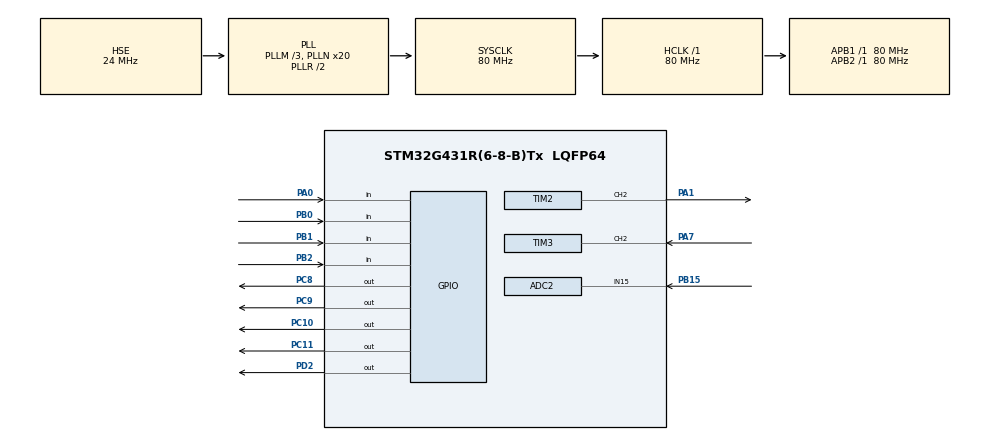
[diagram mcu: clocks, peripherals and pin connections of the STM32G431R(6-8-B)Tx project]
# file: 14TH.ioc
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ADC2.Channel-0\#ChannelRegularConversion=ADC_CHANNEL_15
ADC2.NbrOfConversionFlag=1
ADC2.OffsetNumber-0\#ChannelRegularConversion=ADC_OFFSET_NONE
ADC2.Rank-0\#ChannelRegularConversion=1
ADC2.SamplingTime-0\#ChannelRegularConversion=ADC_SAMPLETIME_2CYCLES_5
Mcu.Family=STM32G4
Mcu.Name=STM32G431R(6-8-B)Tx
Mcu.Package=LQFP64
NVIC.PriorityGroup=NVIC_PRIORITYGROUP_4
NVIC.TIM2_IRQn=true\:0\:0\:true\:false\:true\:true\:true\:true
NVIC.TIM3_IRQn=true\:0\:0\:true\:false\:true\:true\:true\:true
PA0.Signal=GPIO_Input
PA1.Signal=S_TIM2_CH2
PA13.Mode=Serial_Wire
PA13.Signal=SYS_JTMS-SWDIO
PA14.Mode=Serial_Wire
PA14.Signal=SYS_JTCK-SWCLK
PA7.Signal=S_TIM3_CH2
PB0.Signal=GPIO_Input
PB1.Signal=GPIO_Input
PB15.Mode=IN15-Single-Ended
PB15.Signal=ADC2_IN15
PB2.Signal=GPIO_Input
PC10.Signal=GPIO_Output
PC11.Signal=GPIO_Output
PC8.Signal=GPIO_Output
PC9.Signal=GPIO_Output
PD2.Signal=GPIO_Output
PF0-OSC_IN.Mode=HSE-External-Oscillator
PF0-OSC_IN.Signal=RCC_OSC_IN
PF1-OSC_OUT.Mode=HSE-External-Oscillator
PF1-OSC_OUT.Signal=RCC_OSC_OUT
ProjectManager.HeapSize=0x200
ProjectManager.StackSize=0x400
ProjectManager.TargetToolchain=MDK-ARM V5.32
RCC.ADC12Freq_Value=80000000
RCC.AHBFreq_Value=80000000
RCC.APB1Freq_Value=80000000
RCC.APB1TimFreq_Value=80000000
RCC.APB2Freq_Value=80000000
RCC.APB2TimFreq_Value=80000000
RCC.CortexFreq_Value=80000000
RCC.EXTERNAL_CLOCK_VALUE=12288000
RCC.HCLKFreq_Value=80000000
RCC.HSE_VALUE=24000000
RCC.HSI48_VALUE=48000000
RCC.HSI_VALUE=16000000
RCC.LSE_VALUE=32768
RCC.PLLM=RCC_PLLM_DIV3
RCC.PLLN=20
RCC.PLLSourceVirtual=RCC_PLLSOURCE_HSE
RCC.SYSCLKFreq_VALUE=80000000
RCC.SYSCLKSource=RCC_SYSCLKSOURCE_PLLCLK
RCC.USBFreq_Value=80000000
RCC.VCOOutputFreq_Value=160000000
SH.S_TIM2_CH2.0=TIM2_CH2,PWM Generation2 CH2
SH.S_TIM3_CH2.0=TIM3_CH2,Input_Capture2_from_TI2
TIM2.AutoReloadPreload=TIM_AUTORELOAD_PRELOAD_DISABLE
TIM2.Channel-PWM\ Generation2\ CH2=TIM_CHANNEL_2
TIM2.PeriodNoDither=199
TIM2.Prescaler=99
TIM2.PulseNoDither_2=20
TIM3.AutoReloadPreload=TIM_AUTORELOAD_PRELOAD_DISABLE
TIM3.Channel-Input_Capture1_from_TI2_63=TIM_CHANNEL_1
TIM3.Channel-Input_Capture2_from_TI2=TIM_CHANNEL_2
TIM3.ICPolarity_CH1=TIM_INPUTCHANNELPOLARITY_FALLING
TIM3.ICPolarity_CH2=TIM_INPUTCHANNELPOLARITY_RISING
TIM3.Prescaler=79
VP_SYS_VS_DBSignals.Mode=DisableDeadBatterySignals
VP_TIM2_VS_ClockSourceINT.Mode=Internal
VP_TIM3_VS_ClockSourceINT.Mode=Internal
VP_TIM3_VS_indirect_ch2.Mode=Input_Capture1_from_TI2_63
board=custom

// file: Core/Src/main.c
/* USER CODE BEGIN Header */
/**
  ******************************************************************************
  * @file           : main.c
  * @brief          : Main program body
  ******************************************************************************
  * @attention
  *
  * Copyright (c) 2024 STMicroelectronics.
  * All rights reserved.
  *
  * This software is licensed under terms that can be found in the LICENSE file
  * in the root directory of this software component.
  * If no LICENSE file comes with this software, it is provided AS-IS.
  *
  ******************************************************************************
  */
/* USER CODE END Header */
#include "main.h"
#include "adc.h"
#include "tim.h"
#include "gpio.h"

/* USER CODE BEGIN Includes */
#include "key.h"
#include "led.h"
#include "lcd.h"

/* USER CODE END Includes */

void SystemClock_Config(void);

int main(void)
{

  /* MCU Configuration--------------------------------------------------------*/

  /* Reset of all peripherals, Initializes the Flash interface and the Systick. */
  HAL_Init();

  /* Configure the system clock */
  SystemClock_Config();

  /* Initialize all configured peripherals */
  MX_GPIO_Init();
  MX_ADC2_Init();
  MX_TIM3_Init();
  MX_TIM2_Init();
  /* USER CODE BEGIN 2 */
    LCD_Init();
	  LCD_Clear(Black);
    LCD_SetBackColor(Black);
    LCD_SetTextColor(White);
		led_dsp(0X00);
		HAL_TIM_PWM_Start(&htim2,TIM_CHANNEL_2);
	HAL_TIM_IC_Start(&htim3,TIM_CHANNEL_1);
	HAL_TIM_IC_Start_IT(&htim3,TIM_CHANNEL_2);
  /* USER CODE END 2 */

  /* Infinite loop */
   while (1)
  {

    /* USER CODE BEGIN 3 */
		//calculate();
	calculate();
	key_proc();
	lcd_proc();

  }
  /* USER CODE END 3 */
}

void SystemClock_Config(void)
{
  RCC_OscInitTypeDef RCC_OscInitStruct = {0};
  RCC_ClkInitTypeDef RCC_ClkInitStruct = {0};

  /** Configure the main internal regulator output voltage
  */
  HAL_PWREx_ControlVoltageScaling(PWR_REGULATOR_VOLTAGE_SCALE1);

  /** Initializes the RCC Oscillators according to the specified parameters
  * in the RCC_OscInitTypeDef structure.
  */
  RCC_OscInitStruct.OscillatorType = RCC_OSCILLATORTYPE_HSE;
  RCC_OscInitStruct.HSEState = RCC_HSE_ON;
  RCC_OscInitStruct.PLL.PLLState = RCC_PLL_ON;
  RCC_OscInitStruct.PLL.PLLSource = RCC_PLLSOURCE_HSE;
  RCC_OscInitStruct.PLL.PLLM = RCC_PLLM_DIV3;
  RCC_OscInitStruct.PLL.PLLN = 20;
  RCC_OscInitStruct.PLL.PLLP = RCC_PLLP_DIV2;
  RCC_OscInitStruct.PLL.PLLQ = RCC_PLLQ_DIV2;
  RCC_OscInitStruct.PLL.PLLR = RCC_PLLR_DIV2;
  if (HAL_RCC_OscConfig(&RCC_OscInitStruct) != HAL_OK)
  {
    Error_Handler();
  }

  /** Initializes the CPU, AHB and APB buses clocks
  */
  RCC_ClkInitStruct.ClockType = RCC_CLOCKTYPE_HCLK|RCC_CLOCKTYPE_SYSCLK
                              |RCC_CLOCKTYPE_PCLK1|RCC_CLOCKTYPE_PCLK2;
  RCC_ClkInitStruct.SYSCLKSource = RCC_SYSCLKSOURCE_PLLCLK;
  RCC_ClkInitStruct.AHBCLKDivider = RCC_SYSCLK_DIV1;
  RCC_ClkInitStruct.APB1CLKDivider = RCC_HCLK_DIV1;
  RCC_ClkInitStruct.APB2CLKDivider = RCC_HCLK_DIV1;

  if (HAL_RCC_ClockConfig(&RCC_ClkInitStruct, FLASH_LATENCY_2) != HAL_OK)
  {
    Error_Handler();
  }
}

void Error_Handler(void)
{
  __disable_irq();
  while (1)
  {
  }
}
